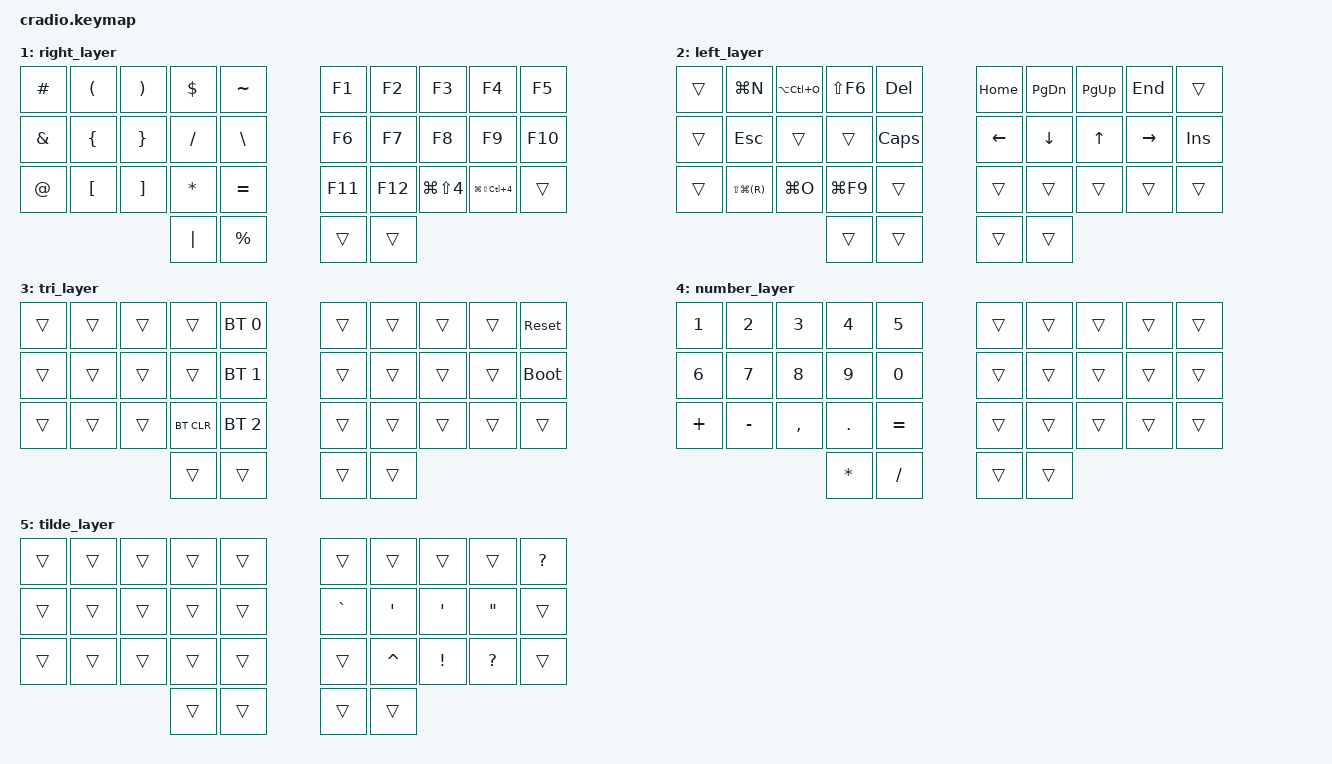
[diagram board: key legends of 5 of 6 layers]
// Copyright (c) 2022 The ZMK Contributors
// SPDX-License-Identifier: MIT

#include <behaviors.dtsi>
#include <dt-bindings/zmk/keys.h>
#include <dt-bindings/zmk/bt.h>

// Home row mods macro
#define HRML(k1,k2,k3,k4) &ht LCTRL k1  &ht LALT k2  &ht LGUI k3  &ht LSHFT k4
#define HRMR(k1,k2,k3,k4) &ht RSHFT k1  &ht RGUI k2  &ht RALT k3  &ht RCTRL k4

#define CAPW &kp LG(LS(N3)) // Capture whole screen 
#define CPYW &kp LG(LS(LC(N3))) // Copy whole screen 
#define CAPP &kp LG(LS(N4)) // Capture portion of screen   
#define CPYP &kp LG(LS(LC(N4))) // Copy portion of screen


//intellij shortcuts
#define RENAME &kp LS(F6)
#define IMPOR &kp LA(LC(O))
#define GENER &kp LG(N)
#define COMPI &kp LG(F9)
#define SEARCH &kp LS(LG((R)))
#define OPEN &kp LG(O)

/ {
    behaviors {
        ht: hold_tap {
            compatible = "zmk,behavior-hold-tap";
            #binding-cells = <2>;
            flavor = "balanced";
            tapping-term-ms = <190>;
            quick-tap-ms = <0>;
            bindings = <&kp>, <&kp>;
        };
    };

    conditional_layers {
        compatible = "zmk,conditional-layers";
        tri_layer {
            if-layers = <1 2>;
            then-layer = <3>;
        };
    };

    keymap {
        compatible = "zmk,keymap";

        //layer number 0
        default_layer {
            bindings = <
        //╭──────────┬──────────┬──────────┬──────────┬──────────╮   ╭──────────┬──────────┬──────────┬──────────┬──────────╮
        //│  Q       │  W       │  E       │  R       │  T       │   │  Y       │  U       │  I       │  O       │  P       │
            &lt 3 Q      &kp W      &kp E      &kp R      &kp T          &kp Y      &kp U      &kp I      &kp O      &kp P
        //├──────────┼──────────┼──────────┼──────────┼──────────┤   ├──────────┼──────────┼──────────┼──────────┼──────────┤
        //│  A       │  S       │  D       │  F       │  G       │   │  H       │  J       │  K       │  L       │ BSPC     │
            HRML(A,        S,         D,         F)     &lt 5 G       &lt 4 H      HRMR(J,        K,         L,        BSPC)
        //├──────────┼──────────┼──────────┼──────────┼──────────┤   ├──────────┼──────────┼──────────┼──────────┼──────────┤
        //│  Z       │  X       │  C       │  V       │  B       │   │  N       │  M       │ , <      │ . >      │ ; :      │
            &kp Z      &kp X      &kp C      &kp V      &kp B          &kp N      &kp M      &kp COMMA  &kp DOT    &kp SEMI
        //╰──────────┴──────────┴──────────┼──────────┼──────────┤   ├──────────┼──────────┼──────────┴──────────┴──────────╯
                                            &ht RGUI TAB   &lt 2 SPACE     &lt 1 ENTER  &ht RGUI MINUS
        //                                 ╰──────────┴──────────╯   ╰──────────┴──────────╯
            >;
        };

        //layer number 1
        right_layer {
            bindings = <
        //╭──────────┬──────────┬──────────┬──────────┬──────────╮   ╭──────────┬──────────┬──────────┬──────────┬──────────╮
        //│  #       │  (       │    )     │  $       │    ~     │   │   F1     │    F2    │   F3     │    F4    │   F5     │
             &kp HASH &kp LPAR &kp RPAR    &kp DOLLAR   &kp TILDE       &kp F1      &kp F2     &kp F3     &kp F4    &kp F5
        //├──────────┼──────────┼──────────┼──────────┼──────────┤   ├──────────┼──────────┼──────────┼──────────┼──────────┤
        //│  &       │   {      │    }     │  /       │    \     │   │   F6     │    F7    │   F8     │    F9    │   F10    │
             &kp AMPS &kp LBRC  &kp RBRC  &kp SLASH  &kp BSLH          &kp F6      &kp F7     &kp F8     &kp F9    &kp F10
        //├──────────┼──────────┼──────────┼──────────┼──────────┤   ├──────────┼──────────┼──────────┼──────────┼──────────┤
        //│    @     │  [       │    ]     │  *       │  =       │   │    F11   │    F12   │ PRSCRN   │  PRSCRN  │          │
            &kp      AT  &kp LBKT  &kp RBKT  &kp ASTRK  &kp EQUAL         &kp F11      &kp F12   CAPP        CPYP       &trans 
        //╰──────────┴──────────┴──────────┼──────────┼──────────┤   ├──────────┼──────────┼──────────┴──────────┴──────────╯
                                             &kp PIPE  &kp PERCENT     &trans     &trans  
        //                                 ╰──────────┴──────────╯   ╰──────────┴──────────╯
            >;
        };


        //layer number 2
        left_layer {
            bindings = <
        //╭──────────┬──────────┬──────────┬──────────┬──────────╮   ╭──────────┬──────────┬──────────┬──────────┬──────────╮
        //│          │GENERATE  │IMPORTS   │ RENAME   │ DELETE   │   │  HOME    │ PG DOWN  │ PG UP    │  END     │          │
            &trans     GENER      IMPOR      RENAME     &kp DEL        &kp HOME  &kp PG_DN  &kp PG_UP   &kp END    &trans
        //├──────────┼──────────┼──────────┼──────────┼──────────┤   ├──────────┼──────────┼──────────┼──────────┼──────────┤
        //│          │ ESC      │          │          │CAPS LOCK │   │  LEFT    │  DOWN    │   UP     │   RIGH   │ INSERT   │
             &trans    &kp ESC    &trans     &trans     &kp CAPS      &kp LEFT   &kp DOWN    &kp UP    &kp RIGHT   &kp INS
        //├──────────┼──────────┼──────────┼──────────┼──────────┤   ├──────────┼──────────┼──────────┼──────────┼──────────┤
        //│          │ SEARCH   │  OPEN    │ COMPILE  │          │   │  &       │  _       │  +       │  │       │          │
            &trans     SEARCH      OPEN       COMPI     &trans         &trans      &trans    &trans      &trans     &trans
        //╰──────────┴──────────┴──────────┼──────────┼──────────┤   ├──────────┼──────────┼──────────┴──────────┴──────────╯
                                             &trans     &trans         &trans     &trans
        //                                 ╰──────────┴──────────╯   ╰──────────┴──────────╯
            >;
        };


        //layer number 3
        tri_layer {
            bindings = <
        //╭──────────┬──────────┬──────────┬──────────┬──────────╮   ╭──────────┬──────────┬──────────┬──────────┬──────────╮
        //│          │          │          │          │PROFILE 0 │   │          │          │          │          │  RESET   │
           &trans      &trans     &trans     &trans    &bt BT_SEL 0    &trans     &trans     &trans     &trans    &sys_reset
        //├──────────┼──────────┼──────────┼──────────┼──────────┤   ├──────────┼──────────┼──────────┼──────────┼──────────┤
        //│          │          │          │          │PROFILE 1 │   │          │          │          │          │BOOTLOADER│
          &trans       &trans     &trans     &trans    &bt BT_SEL 1    &trans     &trans     &trans     &trans    &bootloader
        //├──────────┼──────────┼──────────┼──────────┼──────────┤   ├──────────┼──────────┼──────────┼──────────┼──────────┤
        //│          │          │          │ CLEAR BT │PROFILE 2 │   │          │          │          │          │          │
            &trans     &trans     &trans    &bt BT_CLR &bt BT_SEL 2    &trans     &trans     &trans     &trans     &trans
        //╰──────────┴──────────┴──────────┼──────────┼──────────┤   ├──────────┼──────────┼──────────┴──────────┴──────────╯
                                             &trans     &trans         &trans     &trans
        //                                 ╰──────────┴──────────╯   ╰──────────┴──────────╯
            >;
        };


        //layer number 4
        number_layer {
            bindings = <
        //╭──────────┬──────────┬──────────┬──────────┬──────────╮   ╭──────────┬──────────┬──────────┬──────────┬──────────╮
        //│    1     │  2       │  3       │  4       │  5       │   │          │          │          │          │          │
             &kp N1     &kp N2    &kp N3      &kp N4     &kp N5         &trans     &trans     &trans     &trans     &trans
        //├──────────┼──────────┼──────────┼──────────┼──────────┤   ├──────────┼──────────┼──────────┼──────────┼──────────┤
        //│  6       │  7       │  8       │  9       │  0       │   │          │          │          │          │          │
            &kp N6     &kp N7    &kp N8      &kp N9     &kp N0          &trans     &trans     &trans     &trans     &trans
        //├──────────┼──────────┼──────────┼──────────┼──────────┤   ├──────────┼──────────┼──────────┼──────────┼──────────┤
        //│     +    │    -     │    ,     │    .     │    =     │   │          │          │          │          │          │
           &kp PLUS  &kp MINUS  &kp COMMA  &kp DOT  &kp EQUAL       &trans     &trans     &trans     &trans     &trans
        //╰──────────┴──────────┴──────────┼──────────┼──────────┤   ├──────────┼──────────┼──────────┴──────────┴──────────╯
                                             &kp ASTRK  &kp SLASH    &trans     &trans
        //                                 ╰──────────┴──────────╯   ╰──────────┴──────────╯
            >;
        };

       //layer number 5
       tilde_layer {
            bindings = <
        //╭──────────┬──────────┬──────────┬──────────┬──────────╮   ╭──────────┬──────────┬──────────┬──────────┬──────────╮
        //│          │          │          │          │          │   │          │          │          │          │   ?      │
             &trans     &trans     &trans     &trans     &trans         &trans    &trans    &trans     &trans    &kp QMARK
        //├──────────┼──────────┼──────────┼──────────┼──────────┤   ├──────────┼──────────┼──────────┼──────────┼──────────┤
        //│          │          │          │          │          │   │   `      │    '     │     '    │    "     │          │
            &trans     &trans     &trans     &trans     &trans       &kp GRAVE  &kp APOS &kp APOS    &kp DQT    &trans
        //├──────────┼──────────┼──────────┼──────────┼──────────┤   ├──────────┼──────────┼──────────┼──────────┼──────────┤
        //│          │          │          │          │          │   │          │    ^     │     !    │     ?     │          │
            &trans     &trans     &trans     &trans     &trans           &trans   &kp CARET   &kp EXCL &kp QMARK     &trans
        //╰──────────┴──────────┴──────────┼──────────┼──────────┤   ├──────────┼──────────┼──────────┴──────────┴──────────╯
                                             &trans     &trans          &trans     &trans
        //                                 ╰──────────┴──────────╯   ╰──────────┴──────────╯
            >;
        };
    };
};
